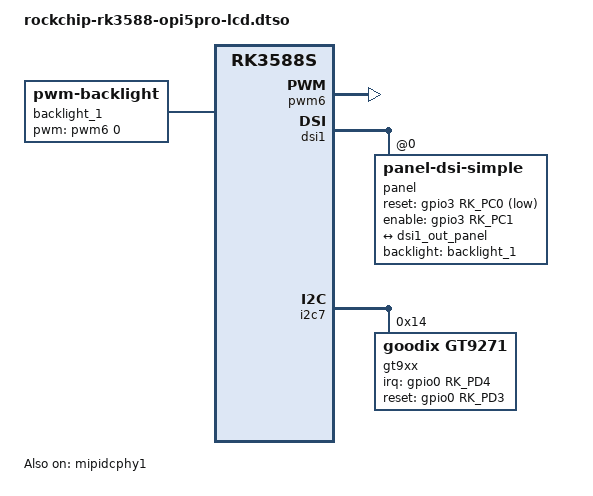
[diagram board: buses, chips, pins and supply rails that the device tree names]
/dts-v1/;
/plugin/;

#include <dt-bindings/gpio/gpio.h>
#include <dt-bindings/interrupt-controller/irq.h>
#include <dt-bindings/pinctrl/rockchip.h>
/* MIPI_DSI_* live in <drm/drm_mipi_dsi.h>, which DT cannot use and which
 * mainline has no dt-bindings copy of. Values from that header:
 *   MODE_VIDEO 1, MODE_VIDEO_BURST 2, MODE_NO_EOT_PACKET 512, MODE_LPM 2048
 *   FMT_RGB888 0
 */
#include <dt-bindings/soc/rockchip,vop2.h>

/ {
	compatible = "xunlong,orangepi-5-pro", "rockchip,rk3588s";
};

/* &{/}, not a bare node in the / block above -- see the matching note in
 * rockchip-rk3588-orangepi-5-lcd-dsi0.dtso. A root-level node here would put
 * "/backlight_1" in __symbols__, which U-Boot's libfdt rejects outright.
 */
&{/} {
	backlight_1: backlight_1 {
		compatible = "pwm-backlight";
		pwms = <&pwm6 0 25000 0>;
		brightness-levels = <0 20 21 22 23 24 25 26 27 28 29 30 31 32 33 34 35 36 37 38 39 40 41 42 43 44 45 46 47 48 49 50 51 52 53 54 55 56 57 58 59 60 61 62 63 64 65 66 67 68 69 70 71 72 73 74 75 76 77 78 79 80 81 82 83 84 85 86 87 88 89 90 91 92 93 94 95 96 97 98 99 100 101 102 103 104 105 106 107 108 109 110 111 112 113 114 115 116 117 118 119 120 121 122 123 124 125 126 127 128 129 130 131 132 133 134 135 136 137 138 139 140 141 142 143 144 145 146 147 148 149 150 151 152 153 154 155 156 157 158 159 160 161 162 163 164 165 166 167 168 169 170 171 172 173 174 175 176 177 178 179 180 181 182 183 184 185 186 187 188 189 190 191 192 193 194 195 196 197 198 199 200 201 202 203 204 205 206 207 208 209 210 211 212 213 214 215 216 217 218 219 220 221 222 223 224 225 226 227 228 229 230 231 232 233 234 235 236 237 238 239 240 241 242 243 244 245 246 247 248 249 250 251 252 253 254 255>;
		default-brightness-level = <200>;
	};
};

&pwm6 {
	status = "okay";
	pinctrl-names = "default";
	pinctrl-0 = <&pwm6m0_pins>;
};

&pinctrl {
	lcd {
		lcd1_rst_gpio: lcd1-rst-gpio {
			rockchip,pins = <3 RK_PC0 RK_FUNC_GPIO &pcfg_pull_none>;
		};
	};
};

&mipidcphy1 {
	status = "okay";
};

&dsi1 {
	#address-cells = <1>;
	#size-cells = <0>;
	status = "okay";

	panel: panel@0 {
		compatible = "panel-dsi-simple";
		reg = <0>;
		status = "okay";
		backlight = <&backlight_1>;
		reset-gpios = <&gpio3 RK_PC0 GPIO_ACTIVE_LOW>;
		enable-gpios = <&gpio3 RK_PC1 GPIO_ACTIVE_HIGH>;
		pinctrl-names = "default";
		pinctrl-0 = <&lcd1_rst_gpio>;

		/* 2051, matching the vendor driver -- see -lcd-dsi0.dtso. */
		dsi,flags = <2051>;
		dsi,format = <0>;      /* RGB888 */
		dsi,lanes = <4>;

		/* Same set as -lcd-dsi0.dtso; see the note there. */
		prepare-delay-ms = <25>;
		reset-delay-ms = <25>;
		init-delay-ms = <200>;
		enable-delay-ms = <150>;
		unprepare-delay-ms = <200>;

		width-mm = <136>;
		height-mm = <217>;

		panel-init-sequence = [
				39 00 04 FF 98 81 03
				15 00 02 01 00
				15 00 02 02 00
				15 00 02 03 53
				15 00 02 04 D3
				15 00 02 05 00
				15 00 02 06 0D
				15 00 02 07 08
				15 00 02 08 00
				15 00 02 09 00
				15 00 02 0a 00
				15 00 02 0b 00
				15 00 02 0c 00
				15 00 02 0d 00
				15 00 02 0e 00
				15 00 02 0f 28
				15 00 02 10 28
				15 00 02 11 00
				15 00 02 12 00
				15 00 02 13 00
				15 00 02 14 00
				15 00 02 15 00
				15 00 02 16 00
				15 00 02 17 00
				15 00 02 18 00
				15 00 02 19 00
				15 00 02 1a 00
				15 00 02 1b 00
				15 00 02 1c 00
				15 00 02 1d 00
				15 00 02 1e 40
				15 00 02 1f 80
				15 00 02 20 06
				15 00 02 21 01
				15 00 02 22 00
				15 00 02 23 00
				15 00 02 24 00
				15 00 02 25 00
				15 00 02 26 00
				15 00 02 27 00
				15 00 02 28 33
				15 00 02 29 33
				15 00 02 2a 00
				15 00 02 2b 00
				15 00 02 2c 00
				15 00 02 2d 00
				15 00 02 2e 00
				15 00 02 2f 00
				15 00 02 30 00
				15 00 02 31 00
				15 00 02 32 00
				15 00 02 33 00
				15 00 02 34 03
				15 00 02 35 00
				15 00 02 36 00
				15 00 02 37 00
				15 00 02 38 96
				15 00 02 39 00
				15 00 02 3a 00
				15 00 02 3b 00
				15 00 02 3c 00
				15 00 02 3d 00
				15 00 02 3e 00
				15 00 02 3f 00
				15 00 02 40 00
				15 00 02 41 00
				15 00 02 42 00
				15 00 02 43 00
				15 00 02 44 00
				15 00 02 50 00
				15 00 02 51 23
				15 00 02 52 45
				15 00 02 53 67
				15 00 02 54 89
				15 00 02 55 AB
				15 00 02 56 01
				15 00 02 57 23
				15 00 02 58 45
				15 00 02 59 67
				15 00 02 5a 89
				15 00 02 5b AB
				15 00 02 5c CD
				15 00 02 5d EF
				15 00 02 5e 00
				15 00 02 5f 08
				15 00 02 60 08
				15 00 02 61 06
				15 00 02 62 06
				15 00 02 63 01
				15 00 02 64 01
				15 00 02 65 00
				15 00 02 66 00
				15 00 02 67 02
				15 00 02 68 15
				15 00 02 69 15
				15 00 02 6a 14
				15 00 02 6b 14
				15 00 02 6c 0D
				15 00 02 6d 0D
				15 00 02 6e 0C
				15 00 02 6f 0C
				15 00 02 70 0F
				15 00 02 71 0F
				15 00 02 72 0E
				15 00 02 73 0E
				15 00 02 74 02
				15 00 02 75 08
				15 00 02 76 08
				15 00 02 77 06
				15 00 02 78 06
				15 00 02 79 01
				15 00 02 7a 01
				15 00 02 7b 00
				15 00 02 7c 00
				15 00 02 7d 02
				15 00 02 7e 15
				15 00 02 7f 15
				15 00 02 80 14
				15 00 02 81 14
				15 00 02 82 0D
				15 00 02 83 0D
				15 00 02 84 0C
				15 00 02 85 0C
				15 00 02 86 0F
				15 00 02 87 0F
				15 00 02 88 0E
				15 00 02 89 0E
				15 00 02 8A 02
				39 00 04 FF 98 81 04
				15 00 02 6E 2B
				15 00 02 6F 37
				15 00 02 3A A4
				15 00 02 8D 1A
				15 00 02 87 BA
				15 00 02 B2 D1
				15 00 02 88 0B
				15 00 02 38 01
				15 00 02 39 00
				15 00 02 B5 07
				15 00 02 31 75
				15 00 02 3B 98
				39 00 04 FF 98 81 01
				15 00 02 43 33
				15 00 02 22 0A
				15 00 02 31 00
				15 00 02 53 48
				15 00 02 55 48
				15 00 02 50 99
				15 00 02 51 94
				15 00 02 60 10
				15 00 02 62 20
				15 00 02 A0 00
				15 00 02 A1 00
				15 00 02 A2 15
				15 00 02 A3 14
				15 00 02 A4 1B
				15 00 02 A5 2F
				15 00 02 A6 25
				15 00 02 A7 24
				15 00 02 A8 80
				15 00 02 A9 1F
				15 00 02 AA 2C
				15 00 02 AB 6C
				15 00 02 AC 16
				15 00 02 AD 14
				15 00 02 AE 4D
				15 00 02 AF 20
				15 00 02 B0 29
				15 00 02 B1 4F
				15 00 02 B2 5F
				15 00 02 B3 23
				15 00 02 C0 00
				15 00 02 C1 2E
				15 00 02 C2 3B
				15 00 02 C3 15
				15 00 02 C4 16
				15 00 02 C5 28
				15 00 02 C6 1A
				15 00 02 C7 1C
				15 00 02 C8 A7
				15 00 02 C9 1B
				15 00 02 CA 28
				15 00 02 CB 92
				15 00 02 CC 1F
				15 00 02 CD 1C
				15 00 02 CE 4B
				15 00 02 CF 1F
				15 00 02 D0 28
				15 00 02 D1 4E
				15 00 02 D2 5C
				15 00 02 D3 23
				39 00 04 FF 98 81 00
				15 00 02 11 00
				15 78 02 29 00
				15 00 02 35 00
		];
		display-timings {
			native-mode = <&panel_timing>;

			panel_timing: timing0 {
				/* 58.26 Hz at the vendor's own clock -- see
				 * the note in -lcd-dsi0.dtso.
				 * 62100000 / (820 * 1300) = 58.26 Hz.
				 */
				clock-frequency = <62100000>;
				hactive = <800>;
				hfront-porch = <10>;
				hback-porch = <5>;
				hsync-len = <5>;
				vactive = <1280>;
				vfront-porch = <5>;
				vback-porch = <10>;
				vsync-len = <5>;
				hsync-active = <0>;
				vsync-active = <0>;
				de-active = <1>;
				pixelclk-active = <0>;
			};
		};


		port {
			panel_in_dsi1: endpoint {
				remote-endpoint = <&dsi1_out_panel>;
			};
		};
	};
};

&dsi1_out {
	dsi1_out_panel: endpoint {
		remote-endpoint = <&panel_in_dsi1>;
	};
};

&dsi1_in {
	dsi1_in_vp3: endpoint {
		remote-endpoint = <&vp3_out_dsi1>;
	};
};

&vp3 {
	#address-cells = <1>;
	#size-cells = <0>;

	vp3_out_dsi1: endpoint@ROCKCHIP_VOP2_EP_MIPI1 {
		reg = <ROCKCHIP_VOP2_EP_MIPI1>;
		remote-endpoint = <&dsi1_in_vp3>;
	};
};

&i2c7 {
	/* restated for dtc, which checks this fragment without the base tree */
	#address-cells = <1>;
	#size-cells = <0>;

	gt9xx: touchscreen@14 {
		compatible = "goodix,gt9271";
		reg = <0x14>;
		status = "okay";

                interrupt-parent = <&gpio0>;
                interrupts = <RK_PD4 IRQ_TYPE_LEVEL_LOW>;
                irq-gpios = <&gpio0 RK_PD4 IRQ_TYPE_LEVEL_LOW>;
                reset-gpios = <&gpio0 RK_PD3 GPIO_ACTIVE_HIGH>;

		touchscreen-size-x = <1280>;
		touchscreen-size-y = <800>;
		touchscreen-swapped-x-y;
		touchscreen-inverted-x;
	};
};
